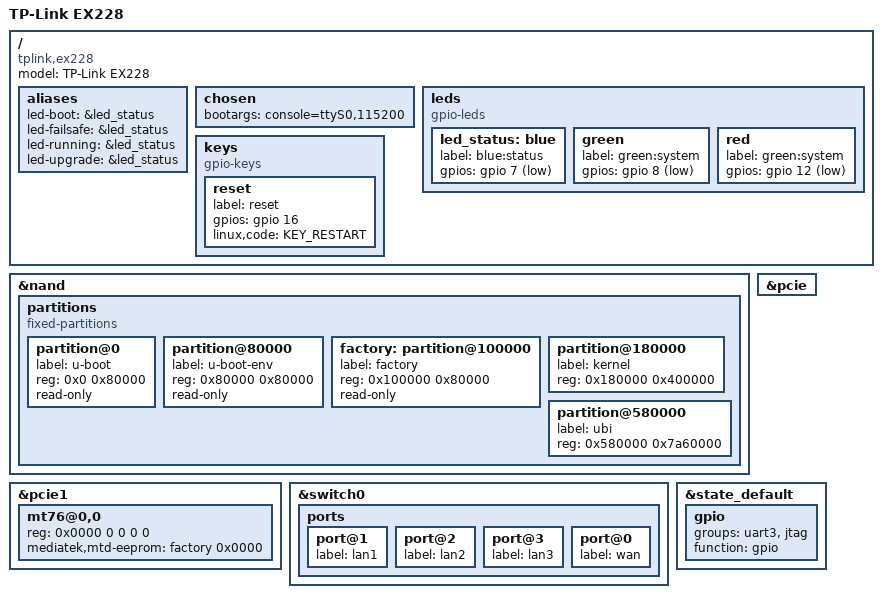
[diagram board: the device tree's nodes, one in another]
#include "mt7621.dtsi"

#include <dt-bindings/gpio/gpio.h>
#include <dt-bindings/input/input.h>

/ {
	compatible = "tplink,ex228", "mediatek,mt7621-soc";
	model = "TP-Link EX228";

	aliases {
		led-boot = &led_status;
		led-failsafe = &led_status;
		led-running = &led_status;
		led-upgrade = &led_status;
	};

	chosen {
		bootargs = "console=ttyS0,115200";
	};

	leds {
		compatible = "gpio-leds";

		led_status: blue {
			label = "blue:status";
			gpios = <&gpio 7 GPIO_ACTIVE_LOW>;
		};

		green {
			label = "green:system";
			gpios = <&gpio 8 GPIO_ACTIVE_LOW>;
		};

		red {
			label = "green:system";
			gpios = <&gpio 12 GPIO_ACTIVE_LOW>;
		};
	};

	keys {
		compatible = "gpio-keys";

		reset {
			label = "reset";
			gpios = <&gpio 16 GPIO_ACTIVE_HIGH>;
			linux,code = <KEY_RESTART>;
		};
	};
};

&nand {
	status = "okay";

	partitions {
		compatible = "fixed-partitions";
		#address-cells = <1>;
		#size-cells = <1>;

		partition@0 {
			label = "u-boot";
			reg = <0x0 0x80000>;
			read-only;
		};

		partition@80000 {
			label = "u-boot-env";
			reg = <0x80000 0x80000>;
			read-only;
		};

		factory: partition@100000 {
			label = "factory";
			reg = <0x100000 0x80000>;
			read-only;
		};

		partition@180000 {
			label = "kernel";
			reg = <0x180000 0x400000>;
		};

		partition@580000 {
			label = "ubi";
			reg = <0x580000 0x7a60000>;
		};
	};
};

&pcie {
	status = "okay";
};

&pcie1 {
	mt76@0,0 {
		reg = <0x0000 0 0 0 0>;
		mediatek,mtd-eeprom = <&factory 0x0000>;
	};
};

&switch0 {
	ports {
		port@1 {
			status = "okay";
			label = "lan1";
		};

		port@2 {
			status = "okay";
			label = "lan2";
		};

		port@3 {
			status = "okay";
			label = "lan3";
		};

		port@0 {
			status = "okay";
			label = "wan";
		};
	};
};

&state_default {
	gpio {
		groups = "uart3", "jtag";
		function = "gpio";
	};
};
